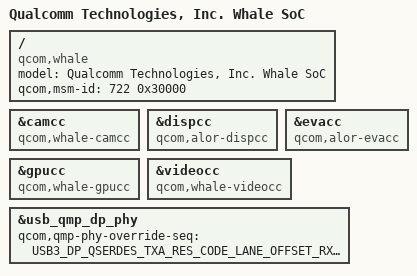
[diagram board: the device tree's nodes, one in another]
// SPDX-License-Identifier: BSD-3-Clause
/*
 * Copyright (c) Qualcomm Technologies, Inc. and/or its subsidiaries.
 */

#include "canoe-v2.dtsi"

/ {
	model = "Qualcomm Technologies, Inc. Whale SoC";
	compatible = "qcom,whale";
	qcom,msm-id = <722 0x30000>;
};

&camcc {
	compatible = "qcom,whale-camcc", "syscon";
};

&dispcc {
	compatible = "qcom,alor-dispcc", "syscon";
};

&evacc {
	compatible = "qcom,alor-evacc", "syscon";
};

&gpucc {
	compatible = "qcom,whale-gpucc", "syscon";
};

&videocc {
	compatible = "qcom,whale-videocc", "syscon";
};

&usb_qmp_dp_phy {
	qcom,qmp-phy-override-seq =
	<USB3_DP_QSERDES_TXA_RES_CODE_LANE_OFFSET_RX 0x04
	 USB3_DP_QSERDES_TXA_LANE_MODE_1 0xF5
	 USB3_DP_QSERDES_TXA_LANE_MODE_3 0x37
	 USB3_DP_QSERDES_TXA_LANE_MODE_4 0x36
	 USB3_DP_QSERDES_RXA_RX_MODE_00_LOW 0X27
	 USB3_DP_QSERDES_RXA_RX_MODE_00_HIGH 0X97
	 USB3_DP_QSERDES_RXA_RX_MODE_00_HIGH2 0xD8
	 USB3_DP_QSERDES_RXA_RX_MODE_00_HIGH4 0xEA
	 USB3_DP_QSERDES_RXA_RX_MODE_01_HIGH2 0x90
	 USB3_DP_QSERDES_RXA_RX_MODE_01_HIGH4 0xA4
	 USB3_DP_QSERDES_TXB_RES_CODE_LANE_OFFSET_RX 0x04
	 USB3_DP_QSERDES_TXB_LANE_MODE_3 0x37
	 USB3_DP_QSERDES_TXB_LANE_MODE_4 0x36
	 USB3_DP_QSERDES_RXB_RX_MODE_00_LOW 0X27
	 USB3_DP_QSERDES_RXB_RX_MODE_00_HIGH 0X97
	 USB3_DP_QSERDES_RXB_RX_MODE_00_HIGH2 0xD8
	 USB3_DP_QSERDES_RXB_RX_MODE_00_HIGH4 0xEA
	 USB3_DP_QSERDES_RXB_RX_MODE_01_HIGH2 0x90
	 USB3_DP_QSERDES_RXB_RX_MODE_01_HIGH4 0xA4>;
};
